# SDHS_367.0 register map
Vendor: Texas Instruments
Peripheral module from a debugger description file (folder msp430).
Registers are 16-bit, read-write, no defined reset value unless marked. A register's access mark holds for its fields unless they carry their own. Offsets are as the file gives them; lines under a group give offsets from that group; [hi:lo] are bit positions; {n}, {i} and the like mark numbered series; 'fields as' and 'values as' point back to an identical list; <NAME> marks a mode.

## SDHS
0x00 SDHSIIDX ro — Interrupt Index Register
  [15:1] IIDX — SDHS Interrupt Vector Value.
    0=No Interrupt pending; 1=Interrupt Source: RIS.OVF; Interrupt Priority: Highest; 2=Interrupt Source: RIS.ACQDONE; 3=Interrupt Source: RIS.SSTRG; 4=Interrupt Source: RIS.DTRDY; 5=Interrupt Source: RIS.WINHI; 6=Interrupt Source: RIS.WINLO; 7=Reserved; Interrupt; 8=Reserved; Interrupt Priority: Lowest
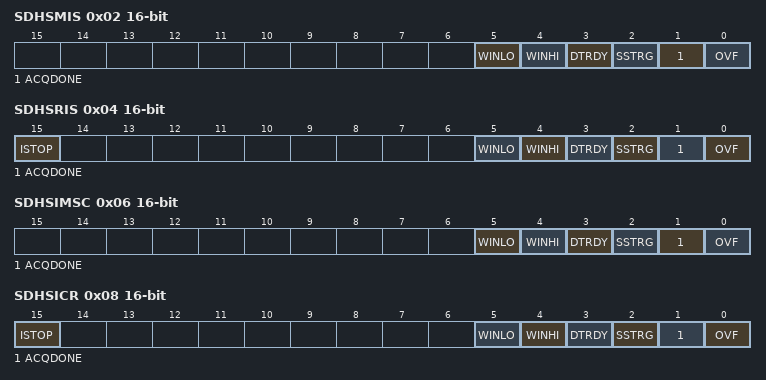
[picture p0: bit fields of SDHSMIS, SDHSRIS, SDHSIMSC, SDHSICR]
0x02 SDHSMIS ro — Masked Interrupt Status and Clear Register
  [all] fields
    0=No interrupt pending; 1=Interrupt pending
  [5] WINLO — SDHS Window Low Masked Interrupt Status and Clear bit.
  [4] WINHI — SDHS Window High Masked Interrupt Status bit.
  [3] DTRDY — SDHS Data Ready Masked Interrupt Status bit.
  [2] SSTRG — SDHS Start Conversion Trigger Masked Interrupt Status bit.
  [1] ACQDONE — Acquisition Done Masked Interrupt Status bit.
  [0] OVF — SDHS Data Overflow Masked Interrupt Status bit.
0x04 SDHSRIS ro — Raw Interrupt Status Register
  [15] ISTOP — Incomplete Stop Status bit.
    0=No ISTOP event; 1=Conversion has been interrupted and stopped before completing the number of samples defined in CTL2.SAMPSZ
  [5] WINLO — SDHS Window Low Raw Interrupt Status bit.
    0=No new data is lower than the value in the WINLOTH register; 1=New data is low than the value in the WINLOTH register
  [4] WINHI — SDHS Window High Raw Interrupt Status bit.
    0=No WINHI event; 1=The output data value is higher than the value in the WINHITH register
  [3] DTRDY — SDHS Data Ready Raw Interrupt Status bit.
    0=No DTRDY event; 1=The data buffer has become empty
  [2] SSTRG — SDHS Start Conversion Trigger Raw Interrupt Status bit.
    0=No SSTRG event; 1=Converson Start signal has been asserted
  [1] ACQDONE — Acquisition Done Raw Interrupt Status bit
    0=No ACQDONE event; 1=Data conversion has been finished (either complete or incomplete)
  [0] OVF — SDHS Data Overflow Raw Interrupt Status bit.
    0=No OVF event; 1=When DTC is enabled (CTL2.DTCOFF = 0), DTC has dropped at least one sample. This indicates that the system clock needs to be increased. When DTC is disabled (CTL2.DTCOFF = 1), At least one new sample has been overwritten to SDHSDT register before the previous value is read.
0x06 SDHSIMSC — Interrupt Mask Register
  [all] fields
    0=Interrupt is disabled; 1=Interrupt is enabled
  [5] WINLO — SDHS Window Low Interrupt Mask bit.
  [4] WINHI — SDHS Window High Interrupt Mask bit.
  [3] DTRDY — SDHS Data Ready Interrupt Mask bit.
  [2] SSTRG — SDHS Start Conversion Trigger Interrupt Mask bit.
  [1] ACQDONE — Acquisition Done Interrupt Mask bit.
  [0] OVF — SDHS Data Overflow Interrupt Mask bit.
0x08 SDHSICR — Interrupt Clear Register.
  [15] ISTOP — Incomplete Stop Interrupt Clear bit.
  [5] WINLO — SDHS Window Low Interrupt Clear bit.
  [4] WINHI — SDHS Window High Interrupt Clear bit.
  [3] DTRDY — SDHS Data Ready Interrupt Clear bit.
  [2] SSTRG — SDHS Start Conversion Trigger Interrupt Clear bit.
  [1] ACQDONE — Acquisition Done Interrupt Clear bit.
  [0] OVF — SDHS Data Overflow Interrupt Clear bit.
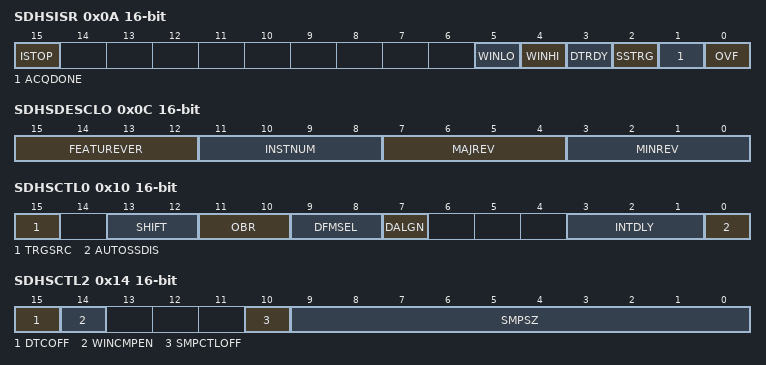
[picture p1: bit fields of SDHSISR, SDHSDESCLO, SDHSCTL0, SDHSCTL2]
0x0A SDHSISR — Interrupt Set Register.
  [15] ISTOP — Incomplete Stop Interrupt Set bit.
  [5] WINLO — SDHS Window Low Interrupt Set bit.
  [4] WINHI — SDHS Window High Interrupt Set bit.
  [3] DTRDY — SDHS Data Ready Interrupt Set bit.
  [2] SSTRG — SDHS Start Conversion Trigger Interrupt Set bit.
  [1] ACQDONE — Acquisition Done Interrupt Set bit.
  [0] OVF — SDHS Data Overflow Interrupt Set bit.
0x0C SDHSDESCLO ro — SDHS Descriptor Register L.
  [15:12] FEATUREVER — Feature Set for the module
  [11:8] INSTNUM — Instance Number within the device.
  [7:4] MAJREV — Major Revision
  [3:0] MINREV — Minor Revision
0x0E SDHSDESCHI access not given — SDHS Descriptor Register H.
0x10 SDHSCTL0 — SDHS Control Register 0
  [15] TRGSRC — SDHS trigger source select.
    0=Register control mode: - CTL4.SDHSON is the source of the SHDS_PWR_UP/DOWN signal - CTL5.SSTART is the source of the CONVERSION_START/STOP signal; 1=ASQ control mode: The SDHS is controlled by the ASQ. - ASQ_ACQARM signal from the ASQ is the source of the SHDS_PWR_UP/DOWN signal - ASQ_ACQTRIG signal from the ASQ is the source of the CONVERSION_START/STOP signal
  [13:12] SHIFT — MSB Shift
    0=No Shift, MSB; 1=MSB - 1 (Shift left by 1 from filter out). If OBR = 2, then this configuration is invalid. No shift is performed.; 2=MSB -2 (Shift left by 2 from filter out). If OBR = 1, then this configuration is invalid. No shift is performed.
  [11:10] OBR — Output Bit Resolution
    0=12-bit; 1=13-bit; 2=14-bit
  [9:8] DFMSEL — Data format
    0=2's complement; 1=Offset binary
  [7] DALGN — Data alignment
    0=Right-aligned; 1=Left-aligned
  [3:1] INTDLY — DTRDY Interrupt delay select. This regiser can be used to discard up to 7 samples after conversion start. Note that the skipped samples will be lost.
    0=No dealy; 1=1 sample delay, 2nd sample is the first interrupt; 2=2 samples delay, 3rd sample is the first interrupt; 3=3 samples delay, 4rd sample is the first interrupt; {v}={v} samples delay, {v+1}th sample is the first interrupt (v=4..7)
  [0] AUTOSSDIS — SDHS Auto Sample Start Disable
    0=Auto Sample start enabled. SDHS is powered up when the SHDS_PWR_UP applied, then data conversion is automatically started once the SDHS is fully powered up.; 1=Auto Sample start disabled. (This configuration must be used when the ASQ controls the measurement sequences) - SHDS_PWR_UP signal to turns on the SDHS - CONVERSION_START signal to start data convesion
0x12 SDHSCTL1 — SDHS Control Register 1
  [3:0] OSR — Over Sampling Rate.
    0=10; 1=20; 2=40; 3=80; 4=160
0x14 SDHSCTL2 — SDHS Control Register 2
  [15] DTCOFF — Data Transfer Controller (DTC) Off
    0=DTC enabled. The DTC automatically transfers the data from the SDHSDT register to the address specified in the DTCDA register.; 1=DTC disabled. The data in the SDHSDT register must be read by CPU, otherwise the overflow interrupt flag (RIS.OVF) will eventually be asserted.
  [14] WINCMPEN — Window Comparator Enable
    0=Window Comparator is disabled; 1=Window Comparator is enabled
  [10] SMPCTLOFF — Disable sampling size counting.
    0=Total sampling size is determined by SMPSZ bits. The SDHS automatically stops data conversion.; 1=SMPSZ bits are ignored. Conversion does not stop until the trigger source selected by TRGSRC bits is deasserted.
  [9:0] SMPSZ — Total Sample Size.
0x16 SDHSCTL3 — SDHS Control Register 3
  [0] TRIGEN — SDHS Trigger Enable bit
    0=SDHS Trigger is disabled. Once this bit is de-asserted, CTL0, CTL1, CTL2, CTL7,WINHITH, WINLOTH, and DTCDA registers are unlocked (allowed to be modified).; 1=SDHS Trigger is enabled. Once this bit is asserted, CTL0, CTL1, CTL2, CTL7,WINHITH, WINLOTH, and DTCDA registers are locked (not allowed to be modified).
0x18 SDHSCTL4 — SDHS Control Register 4
  [0] SDHSON — SDHS Power-up
    0=Power down the SDHS module; 1=Power on the SDHS module
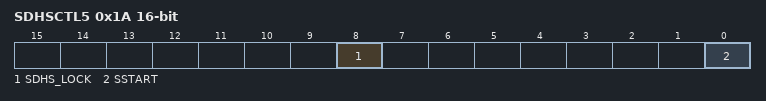
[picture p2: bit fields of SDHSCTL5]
0x1A SDHSCTL5 access per field — SDHS Control Register 5
  [8] SDHS_LOCK ro — Start of conversion.
    0=CTL3 register is unlocked; 1=CTL3 register is locked as well as CTL0, CTL1, CTL2, CTL7,WINHITH, WINLOTH, and DTCDA registers. Only read is allowed.
  [0] SSTART rw — Start of conversion.
    0=Stop conversion; 1=Start conversion
0x1C SDHSCTL6 — SDHS Control Register 6
  [5:0] PGA_GAIN — PGA Gain Control bits
0x1E SDHSCTL7 — SDHS Control Register 7
  [4:0] MODOPTI — SDHS Modulator Optimization bits.
0x22 SDHSDT access not given — SDHS Data Converstion Register
0x24 SDHSWINHITH access not given — SDHS Window Comparator High Threshold Register.
0x26 SDHSWINLOTH access not given — SDHS Window Comparator Low Threshold Register.
0x28 SDHSDTCDA — DTC destination address register
  [14:0] DTCDA — DTC destination address.
